# N32G033 register map
Vendor: Nsingtech Ltd.; File version: 1.0
Registers are 32-bit, read-write, reset 0x0 unless marked. A register's access mark holds for its fields unless they carry their own. Offsets are from the block's base; [hi:lo] are bit positions; {n}, {i} and the like mark numbered series.

## UART1
Base 0x40013800
Same registers: UART2 0x40004400, UART3 0x40004800
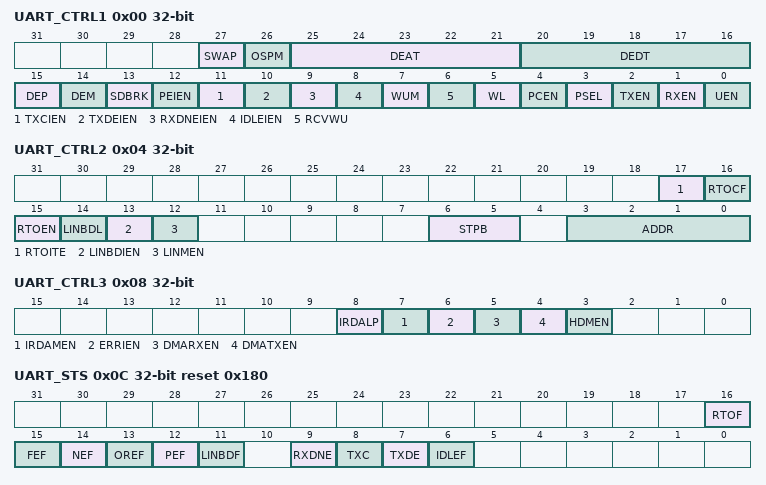
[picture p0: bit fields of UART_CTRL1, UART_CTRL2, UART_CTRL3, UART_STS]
0x00 UART_CTRL1 — UART Baud rate register
  [27] SWAP, [26] OSPM, [25:21] DEAT, [20:16] DEDT, [15] DEP, [14] DEM, [13] SDBRK, [12] PEIEN, [11] TXCIEN, [10] TXDEIEN, [9] RXDNEIEN, [8] IDLEIEN, [7] WUM, [6] RCVWU, [5] WL, [4] PCEN, [3] PSEL, [2] TXEN, [1] RXEN, [0] UEN
0x04 UART_CTRL2 — UART Baud rate register
  [17] RTOITE, [16] RTOCF, [15] RTOEN, [14] LINBDL, [13] LINBDIEN, [12] LINMEN, [6:5] STPB, [3:0] ADDR
0x08 UART_CTRL3 — UART Baud rate register
  [8] IRDALP, [7] IRDAMEN, [6] ERRIEN, [5] DMARXEN, [4] DMATXEN, [3] HDMEN
0x0C UART_STS reset 0x180 — UART Status register
  [16] RTOF, [15] FEF, [14] NEF, [13] OREF, [12] PEF, [11] LINBDF, [9] RXDNE, [8] TXC, [7] TXDE, [6] IDLEF
0x10 UART_DAT — UART Data register
  [8:0] DATV
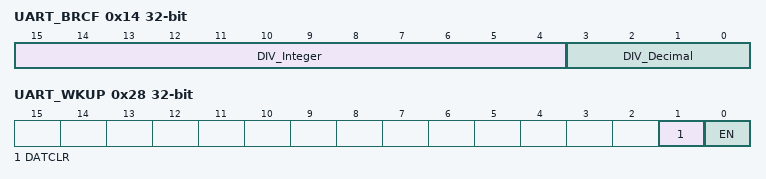
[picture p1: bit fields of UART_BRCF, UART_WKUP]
0x14 UART_BRCF — UART Baud rate register
  [15:4] DIV_Integer, [3:0] DIV_Decimal
0x18 UART_GTP — USART Baud rate register
  [7:0] PSCV
0x24 UART_RTO — UART receiver timeout value.
  [27:0] TIME
0x28 UART_WKUP — UART WAKE UP register
  [1] DATCLR, [0] EN

## HDIV
Base 0x40028000
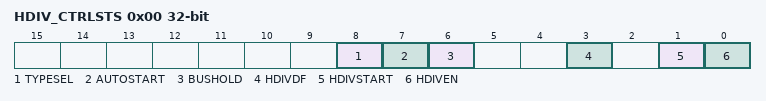
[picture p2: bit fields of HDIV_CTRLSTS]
0x00 HDIV_CTRLSTS — nan
  [8] TYPESEL, [7] AUTOSTART, [6] BUSHOLD, [3] HDIVDF, [1] HDIVSTART, [0] HDIVEN
0x04 HDIV_DIVIDEND — Dividend data
0x08 HDIV_DIVISOR — Divisor data
0x0C HDIV_QUOTIENT — quotient data
0x10 HDIV_REMAINDER — Remainder data
0x14 HDIV_DIVBY0 — nan
  [0] HDIV_DIVBY0

## SQRT
Base 0x40020400
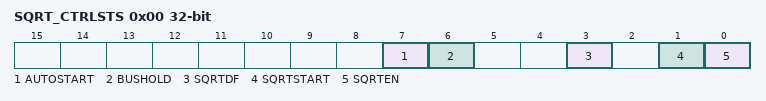
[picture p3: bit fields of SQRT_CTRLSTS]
0x00 SQRT_CTRLSTS — nan
  [7] AUTOSTART, [6] BUSHOLD, [3] SQRTDF, [1] SQRTSTART, [0] SQRTEN
0x04 SQRT_RADICAND — Radicant value
0x08 SQRT_ROOT — nan
  [15:0] ROOT

## SPI1
Base 0x40012000
Same registers: SPI2 0x40014400
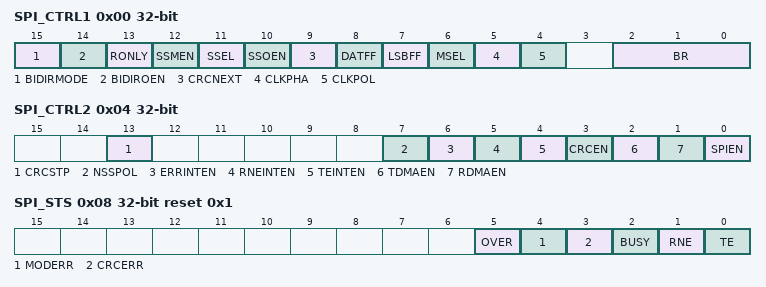
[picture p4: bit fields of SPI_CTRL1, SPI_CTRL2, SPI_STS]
0x00 SPI_CTRL1 — SPI
  [15] BIDIRMODE, [14] BIDIROEN, [13] RONLY, [12] SSMEN, [11] SSEL, [10] SSOEN, [9] CRCNEXT, [8] DATFF, [7] LSBFF, [6] MSEL, [5] CLKPHA, [4] CLKPOL, [2:0] BR
0x04 SPI_CTRL2 — SPI
  [13] CRCSTP, [7] NSSPOL, [6] ERRINTEN, [5] RNEINTEN, [4] TEINTEN, [3] CRCEN, [2] TDMAEN, [1] RDMAEN, [0] SPIEN
0x08 SPI_STS reset 0x1 — SPI
  [5] OVER, [4] MODERR, [3] CRCERR, [2] BUSY, [1] RNE, [0] TE
0x0C SPI_DAT — SPI
  [15:0] DAT
0x10 SPI_CRCTDAT — SPI TX CRC
  [15:0] CRCTDAT
0x14 SPI_CRCRDAT — SPI RX CRC
  [15:0] CRCRDAT
0x18 SPI_CRCPOLY reset 0x7 — SPI CRC
  [15:0] CRCPOLY
0x38 SPI_CTRL3 — SPI
  [3:0] DELAYTIME

## TIM1 — TIM
Base 0x40012C00
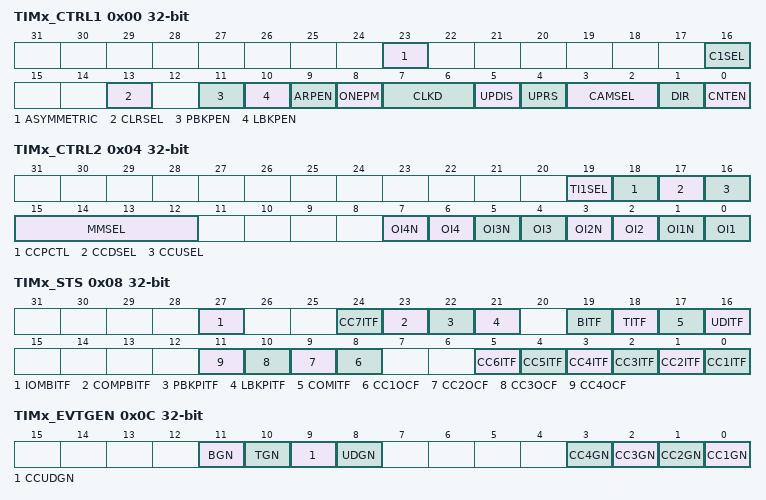
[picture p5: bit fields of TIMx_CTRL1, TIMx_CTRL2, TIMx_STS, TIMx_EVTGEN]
0x00 TIMx_CTRL1 — TIM control register1
  [23] ASYMMETRIC, [16] C1SEL, [13] CLRSEL, [11] PBKPEN, [10] LBKPEN, [9] ARPEN, [8] ONEPM, [7:6] CLKD, [5] UPDIS, [4] UPRS, [3:2] CAMSEL, [1] DIR, [0] CNTEN
0x04 TIMx_CTRL2 — TIM control register2
  [19] TI1SEL, [18] CCPCTL, [17] CCDSEL, [16] CCUSEL, [15:12] MMSEL, [2n-1] OI{n}N (n=1..4), [2n-2] OI{n} (n=1..4)
0x08 TIMx_STS — TIM status register
  [27] IOMBITF, [24] CC7ITF, [23] COMPBITF, [22] PBKPITF, [21] LBKPITF, [19] BITF, [18] TITF, [17] COMITF, [16] UDITF, [n+7] CC{n}OCF (n=1..4), [n-1] CC{n}ITF (n=1..6)
0x0C TIMx_EVTGEN — TIM event generation register
  [11] BGN, [10] TGN, [9] CCUDGN, [8] UDGN, [n-1] CC{n}GN (n=1..4)
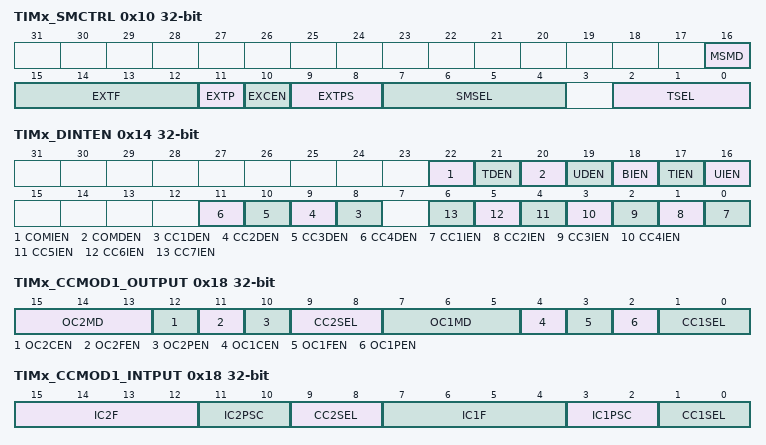
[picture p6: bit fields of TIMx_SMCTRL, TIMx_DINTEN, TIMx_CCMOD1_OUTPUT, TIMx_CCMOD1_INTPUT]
0x10 TIMx_SMCTRL — TIM slave mode control register
  [16] MSMD, [15:12] EXTF, [11] EXTP, [10] EXCEN, [9:8] EXTPS, [7:4] SMSEL, [2:0] TSEL
0x14 TIMx_DINTEN — TIM DMA/Interrupt enable register
  [22] COMIEN, [21] TDEN, [20] COMDEN, [19] UDEN, [18] BIEN, [17] TIEN, [16] UIEN, [n+7] CC{n}DEN (n=1..4), [n-1] CC{n}IEN (n=1..7)
0x18 TIMx_CCMOD1_OUTPUT — TIM capture/compare mode register 1 (output mode)
  [15:13] OC2MD, [12] OC2CEN, [11] OC2FEN, [10] OC2PEN, [9:8] CC2SEL, [7:5] OC1MD, [4] OC1CEN, [3] OC1FEN, [2] OC1PEN, [1:0] CC1SEL
0x18 TIMx_CCMOD1_INTPUT (alternate view of TIMx_CCMOD1_OUTPUT) — TIM capture/compare mode register 1 (intput mode)
  [15:12] IC2F, [11:10] IC2PSC, [9:8] CC2SEL, [7:4] IC1F, [3:2] IC1PSC, [1:0] CC1SEL
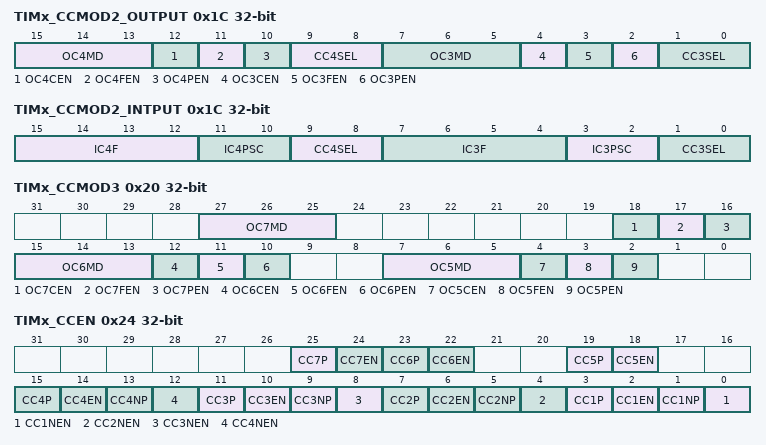
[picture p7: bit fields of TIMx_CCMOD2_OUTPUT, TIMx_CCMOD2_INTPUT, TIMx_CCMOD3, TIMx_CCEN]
0x1C TIMx_CCMOD2_OUTPUT — TIM capture/compare mode register 2 (output mode)
  [15:13] OC4MD, [12] OC4CEN, [11] OC4FEN, [10] OC4PEN, [9:8] CC4SEL, [7:5] OC3MD, [4] OC3CEN, [3] OC3FEN, [2] OC3PEN, [1:0] CC3SEL
0x1C TIMx_CCMOD2_INTPUT (alternate view of TIMx_CCMOD2_OUTPUT) — TIM capture/compare mode register 2 (intput mode)
  [15:12] IC4F, [11:10] IC4PSC, [9:8] CC4SEL, [7:4] IC3F, [3:2] IC3PSC, [1:0] CC3SEL
0x20 TIMx_CCMOD3 — TIM compare mode register 3
  [27:25] OC7MD, [18] OC7CEN, [17] OC7FEN, [16] OC7PEN, [15:13] OC6MD, [12] OC6CEN, [11] OC6FEN, [10] OC6PEN, [7:5] OC5MD, [4] OC5CEN, [3] OC5FEN, [2] OC5PEN
0x24 TIMx_CCEN — TIM capture/compare enable register
  [25] CC7P, [24] CC7EN, [4n-1] CC{n}P (n=1..6), [4n-2] CC{n}EN (n=1..6), [4n-3] CC{n}NP (n=1..4), [4n-4] CC{n}NEN (n=1..4)
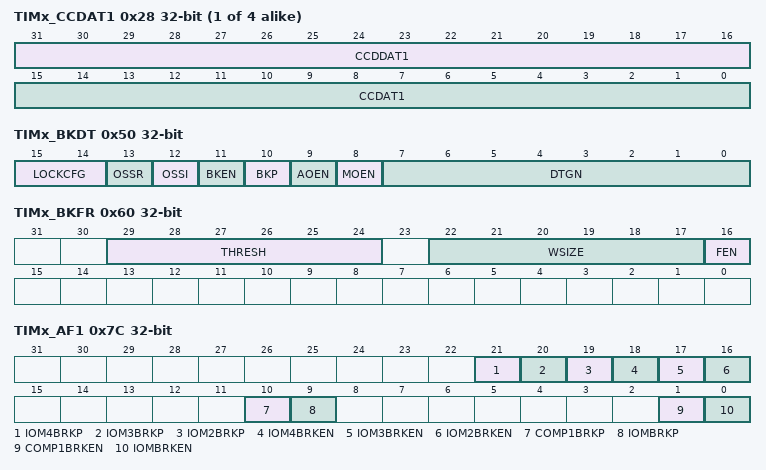
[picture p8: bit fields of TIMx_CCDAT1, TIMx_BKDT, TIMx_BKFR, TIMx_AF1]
{0x24+4i} TIMx_CCDAT{i} (i=1..4) — TIM capture/compare register {i}
  [31:16] CCDDAT{i}, [15:0] CCDAT{i}
0x38 TIMx_CCDAT5 — TIM capture/compare register 5
  [15:0] CCDAT5
0x3C TIMx_CCDAT6 — TIM capture/compare register 6
  [15:0] CCDAT6
0x40 TIMx_PSC — TIM prescaler
  [15:0] PSC
0x44 TIMx_AR reset 0xFFFF — TIM auto-reload register
  [15:0] ARR
0x48 TIMx_CNT — TIM counter
  [15:0] CNT
0x4C TIMx_REPCNT — TIM repetition counter register
  [7:0] REPCNT
0x50 TIMx_BKDT — TIM Break and Deadtime control register
  [15:14] LOCKCFG, [13] OSSR, [12] OSSI, [11] BKEN, [10] BKP, [9] AOEN, [8] MOEN, [7:0] DTGN
0x54 TIMx_CCDAT7 — TIM compare register 7
  [15:0] CCDAT7
0x60 TIMx_BKFR — TIM break 1 Filter
  [29:24] THRESH, [22:17] WSIZE, [16] FEN
0x7C TIMx_AF1 — TIM AF1
  [21] IOM4BRKP, [20] IOM3BRKP, [19] IOM2BRKP, [18] IOM4BRKEN, [17] IOM3BRKEN, [16] IOM2BRKEN, [10] COMP1BRKP, [9] IOMBRKP, [1] COMP1BRKEN, [0] IOMBRKEN
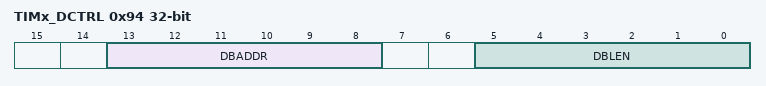
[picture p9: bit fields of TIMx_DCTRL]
0x94 TIMx_DCTRL — TIM DMA control register
  [13:8] DBADDR, [5:0] DBLEN
0x98 TIMx_DADDR — TIM DMA address for full transfer
  [31:0] BURST
